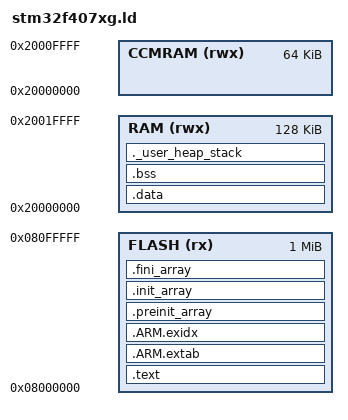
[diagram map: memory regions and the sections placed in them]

_Min_Heap_Size = 0x1000;	/* required amount of heap  */
_Min_Stack_Size = 0x2000;	/* required amount of stack */


/* Linker script to configure memory regions. 
 * Need modifying for a specific board. 
 *   FLASH.ORIGIN: starting address of flash
 *   FLASH.LENGTH: length of flash
 *   RAM.ORIGIN: starting address of RAM bank 0
 *   RAM.LENGTH: length of RAM bank 0
 */
MEMORY
{
  FLASH (rx) : ORIGIN = 0x08000000, LENGTH = 1M
  RAM (rwx) : ORIGIN = 0x20000000, LENGTH = 128K
  CCMRAM (rwx) : ORIGIN = 0x20000000, LENGTH = 64K
}

ENTRY(Reset_Handler)

SECTIONS
{
    .text :
    {
        KEEP(*(.isr_vector))
        . = ALIGN(2048);

        HIDDEN(__rel_isrvector = .);
        KEEP(*(.isr_vector2))
        __rel_isrsize = . - __rel_isrvector;
        . = ALIGN(2048);

        *(.text)
        *(.text*)

        KEEP (*(.init))
        KEEP (*(.fini))

        *(.rodata*)
    } > FLASH

    .ARM.extab : 
    {
        *(.ARM.extab* .gnu.linkonce.armextab.*)
    } > FLASH

    __exidx_start = .;
    .ARM.exidx :
    {
        *(.ARM.exidx* .gnu.linkonce.armexidx.*)
    } > FLASH
    __exidx_end = .;
    

    .preinit_array     :
    {
        . = ALIGN(4);
        PROVIDE_HIDDEN (__preinit_array_start = .);
        KEEP (*(.preinit_array*))
        PROVIDE_HIDDEN (__preinit_array_end = .);
        . = ALIGN(4);
    } >FLASH

    .init_array :
    {
        . = ALIGN(4);
        PROVIDE_HIDDEN (__init_array_start = .);
        KEEP (*(SORT(.init_array.*)))
        KEEP (*(.init_array*))
        PROVIDE_HIDDEN (__init_array_end = .);
        . = ALIGN(4);
    } >FLASH

    .fini_array :
    {
        . = ALIGN(4);
        PROVIDE_HIDDEN (__fini_array_start = .);
        KEEP (*(SORT(.fini_array.*)))
        KEEP (*(.fini_array*))
        PROVIDE_HIDDEN (__fini_array_end = .);
        . = ALIGN(4);
    } >FLASH


    /* Location counter can end up 2byte aligned with narrow Thumb code but
       __etext is assumed by startup code to be the LMA of a section in RAM
       which must be 4byte aligned */
    __etext = ALIGN (4);

    _sidata = LOADADDR(.data);

    .data : AT (__etext)
    {
        . = ALIGN(4);
        _sdata = .;        /* create a global symbol at data start */
        *(.data)
        *(.data*)
        . = ALIGN(4);
        
        . = ALIGN(4);
        _edata = .;        /* define a global symbol at data end */

    } > RAM

    .bss :
    {
        . = ALIGN(4);
        _sbss = .;         /* define a global symbol at bss start */
        __bss_start__ = _sbss;
        *(.bss)
        *(.bss*)
        *(COMMON)
        . = ALIGN(4);
        _ebss = .;         /* define a global symbol at bss end */
        __bss_end__ = _ebss;
    } > RAM

    /* .stack_dummy section doesn't contains any symbols. It is only
     * used for linker to calculate size of stack sections, and assign
     * values to stack symbols later */
    ._user_heap_stack :
    {
        . = ALIGN(8);
        PROVIDE ( end = . );
        PROVIDE ( _end = . );
        . = . + _Min_Heap_Size;
        . = . + _Min_Stack_Size;
        . = ALIGN(8);
    } >RAM

    /* Set stack top to end of RAM, and stack limit move down by
     * size of stack_dummy section */
    PROVIDE_HIDDEN(__StackTop = ORIGIN(RAM) + LENGTH(RAM));
    PROVIDE(_estack = __StackTop);
}
